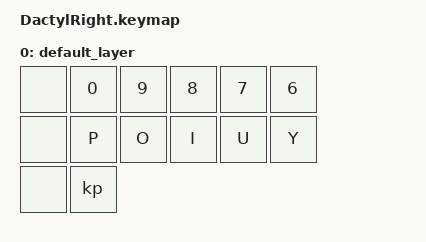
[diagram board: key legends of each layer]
#include <behaviours.dtsi>
#include <dt-bindings/zmk/keys.h>
#include <dt-bindings/zmk/bt.h>

/ {
	keymap {
		compatible = "zmk,keymap";

		default_layer {
			bindings = <
				&none &kp 0 &kp 9 &kp 8 &kp 7 &kp 6
				&none &kp P &kp O &kp I &kp U &kp Y
				&none &kp ; &kp L &kp K &kp J &kp H
				&none &kp / &kp . &kp , &kp M &kp N
				&none &none &none &none &none
				&kp SPACE &kp RSHIFT &none &none &none
			>;
		};
	};
};
